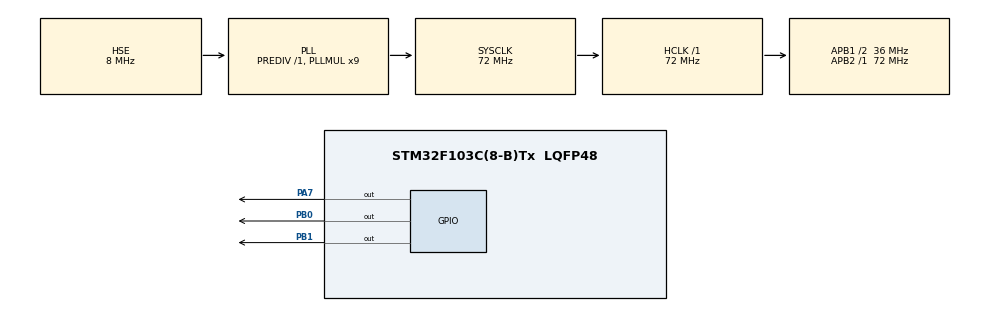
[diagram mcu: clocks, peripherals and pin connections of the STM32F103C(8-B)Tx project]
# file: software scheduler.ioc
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Mcu.Family=STM32F1
Mcu.Name=STM32F103C(8-B)Tx
Mcu.Package=LQFP48
NVIC.PriorityGroup=NVIC_PRIORITYGROUP_4
NVIC.TIM2_IRQn=true\:1\:0\:true\:false\:true\:true\:true\:true
PA7.Signal=GPIO_Output
PB0.Signal=GPIO_Output
PB1.Signal=GPIO_Output
PD0-OSC_IN.Mode=HSE-External-Oscillator
PD0-OSC_IN.Signal=RCC_OSC_IN
PD1-OSC_OUT.Mode=HSE-External-Oscillator
PD1-OSC_OUT.Signal=RCC_OSC_OUT
ProjectManager.HeapSize=0x200
ProjectManager.StackSize=0x400
ProjectManager.TargetToolchain=STM32CubeIDE
RCC.AHBFreq_Value=72000000
RCC.APB1CLKDivider=RCC_HCLK_DIV2
RCC.APB1Freq_Value=36000000
RCC.APB1TimFreq_Value=72000000
RCC.APB2Freq_Value=72000000
RCC.APB2TimFreq_Value=72000000
RCC.HCLKFreq_Value=72000000
RCC.PLLMUL=RCC_PLL_MUL9
RCC.PLLSourceVirtual=RCC_PLLSOURCE_HSE
RCC.SYSCLKFreq_VALUE=72000000
RCC.SYSCLKSource=RCC_SYSCLKSOURCE_PLLCLK
RCC.USBFreq_Value=72000000
TIM2.AutoReloadPreload=TIM_AUTORELOAD_PRELOAD_ENABLE
TIM2.Period=999
TIM2.Prescaler=71
VP_SYS_VS_ND.Mode=No_Debug
VP_TIM2_VS_ClockSourceINT.Mode=Internal
board=custom

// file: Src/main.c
#include "main.h"
#include "tim.h"
#include "gpio.h"

volatile uint32_t system_tick = 0;

void SystemClock_Config(void);

int main(void)
{
    HAL_Init();
    SystemClock_Config();
    MX_GPIO_Init();
    MX_TIM2_Init();

    HAL_TIM_Base_Start_IT(&htim2);

    uint32_t last_LED1 = 0;
    uint32_t last_LED2 = 0;
    uint32_t last_LED3 = 0;

    while (1)
    {
        if ((system_tick - last_LED1) >= 200)
        {
            HAL_GPIO_TogglePin(GPIOB, GPIO_PIN_1);
            last_LED1 = system_tick;
        }

        if ((system_tick - last_LED2) >= 500)
        {
            HAL_GPIO_TogglePin(GPIOB, GPIO_PIN_0);
            last_LED2 = system_tick;
        }

        if ((system_tick - last_LED3) >= 1000)
        {
            HAL_GPIO_TogglePin(GPIOA, GPIO_PIN_7);
            last_LED3 = system_tick;
        }

    }
}

/* USER CODE BEGIN 4 */
void HAL_TIM_PeriodElapsedCallback(TIM_HandleTypeDef *htim)
{
    if (htim->Instance == TIM2)
    {
        system_tick++;
    }
}
/* USER CODE END 4 */

void SystemClock_Config(void)
{
    RCC_OscInitTypeDef RCC_OscInitStruct = {0};
    RCC_ClkInitTypeDef RCC_ClkInitStruct = {0};

    RCC_OscInitStruct.OscillatorType = RCC_OSCILLATORTYPE_HSE;
    RCC_OscInitStruct.HSEState = RCC_HSE_ON;
    RCC_OscInitStruct.HSEPredivValue = RCC_HSE_PREDIV_DIV1;
    RCC_OscInitStruct.HSIState = RCC_HSI_ON;
    RCC_OscInitStruct.PLL.PLLState = RCC_PLL_ON;
    RCC_OscInitStruct.PLL.PLLSource = RCC_PLLSOURCE_HSE;
    RCC_OscInitStruct.PLL.PLLMUL = RCC_PLL_MUL9;
    if (HAL_RCC_OscConfig(&RCC_OscInitStruct) != HAL_OK) { Error_Handler(); }

    RCC_ClkInitStruct.ClockType = RCC_CLOCKTYPE_HCLK | RCC_CLOCKTYPE_SYSCLK
                                | RCC_CLOCKTYPE_PCLK1 | RCC_CLOCKTYPE_PCLK2;
    RCC_ClkInitStruct.SYSCLKSource = RCC_SYSCLKSOURCE_PLLCLK;
    RCC_ClkInitStruct.AHBCLKDivider = RCC_SYSCLK_DIV1;
    RCC_ClkInitStruct.APB1CLKDivider = RCC_HCLK_DIV2;
    RCC_ClkInitStruct.APB2CLKDivider = RCC_HCLK_DIV1;
    if (HAL_RCC_ClockConfig(&RCC_ClkInitStruct, FLASH_LATENCY_2) != HAL_OK) { Error_Handler(); }
}

void Error_Handler(void)
{
    __disable_irq();
    while (1) {}
}
